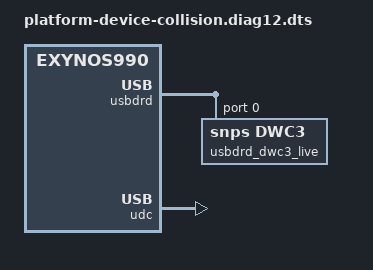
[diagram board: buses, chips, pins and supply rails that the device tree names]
/dts-v1/;
/*
 * Negative control fixture for platform device name collision (issue #5).
 *
 * Reproduces the diag12 bug where the live DWC3 gadget child node
 * (/soc@0/usb@10e00000/usb@0) and the overlay-enabled stock root node
 * (/usb@10E00000) both produce the platform device name "10e00000.usb".
 * When dwc3_exynos_probe() attempts to populate its child, device_add fails
 * with sysfs: cannot create duplicate filename '/bus/platform/devices/10e00000.usb',
 * and the DWC3 core gadget device is never created.
 */
/ {
	compatible = "samsung,exynos990";
	#address-cells = <2>;
	#size-cells = <1>;

	soc: soc@0 {
		compatible = "simple-bus";
		ranges = <0x0 0x0 0x0 0x20000000>;
		#address-cells = <1>;
		#size-cells = <1>;

		usbdrd: usb@10e00000 {
			compatible = "samsung,exynos990-dwusb3", "samsung,exynos850-dwusb3";
			ranges = <0x0 0x10e00000 0x10000>;
			#address-cells = <1>;
			#size-cells = <1>;
			status = "okay";

			usbdrd_dwc3_live: usb@0 {
				compatible = "snps,dwc3";
				reg = <0x0 0x10000>;
				status = "okay";
			};
		};
	};

	udc: usb@10E00000 {
		compatible = "samsung,exynos-dwusb";
		reg = <0x00 0x10e00000 0x10000>;
		status = "okay";
	};
};
